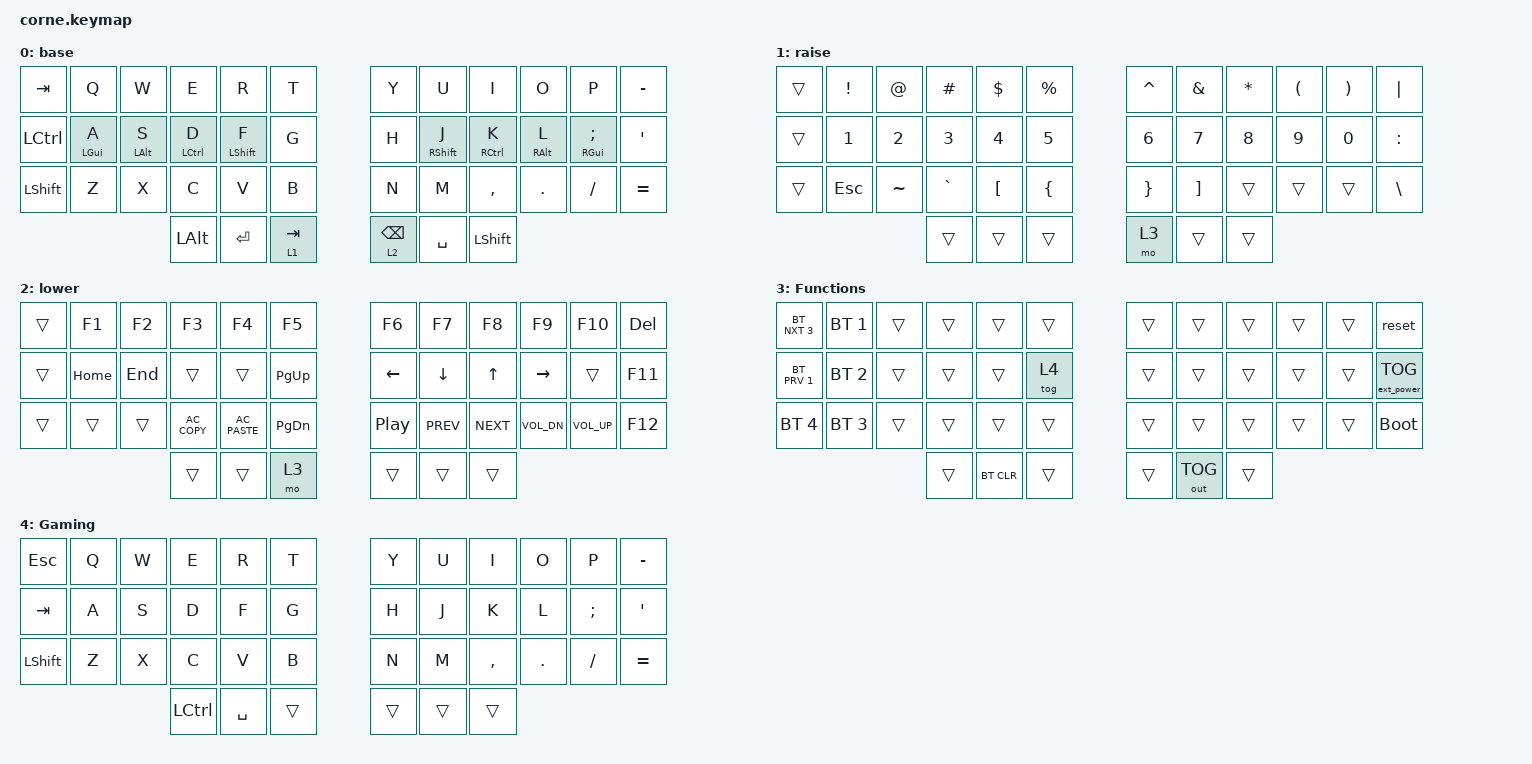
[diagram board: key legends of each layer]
/*
 * Copyright (c) 2020 The ZMK Contributors
 *
 * SPDX-License-Identifier: MIT
 */

#include <behaviors.dtsi>
#include <dt-bindings/zmk/keys.h>
#include <dt-bindings/zmk/bt.h>
#include <dt-bindings/zmk/ext_power.h>
#include <dt-bindings/zmk/outputs.h>

/ {
    behaviors {
        hm: homerow_mods {
            compatible = "zmk,behavior-hold-tap";
            label = "HOMEROW_MODS";
            #binding-cells = <2>;
            tapping-term-ms = <150>;
            quick-tap-ms = <0>;
            flavor = "tap-preferred";
            bindings =
                <&kp>,
                <&kp>;
        };
    };

    combos {
        compatible = "zmk,combos";

        ESCAPE_Combo {
            bindings = <&kp ESC>;
            key-positions = <19 20>;
        };

        Left_Bracket {
            bindings = <&kp LEFT_BRACKET>;
            key-positions = <4 5>;
        };

        Right_Bracket {
            bindings = <&kp RIGHT_BRACKET>;
            key-positions = <6 7>;
        };

        Left_Parethesis {
            bindings = <&kp LEFT_PARENTHESIS>;
            key-positions = <16 17>;
        };

        Right_Parenthesis {
            bindings = <&kp RIGHT_PARENTHESIS>;
            key-positions = <18 19>;
        };

        Left_Brace {
            bindings = <&kp LEFT_BRACE>;
            key-positions = <28 29>;
        };

        Right_Brace {
            bindings = <&kp RIGHT_BRACE>;
            key-positions = <30 31>;
        };

        Back_Slash {
            bindings = <&kp BACKSLASH>;
            key-positions = <4 31>;
        };

        Slash {
            bindings = <&kp SLASH>;
            key-positions = <28 7>;
        };

        Backspace {
            bindings = <&kp BACKSPACE>;
            key-positions = <3 4>;
        };

        Delete {
            bindings = <&kp DELETE>;
            key-positions = <7 8>;
        };

        Toggle_Gaming_Layer {
            bindings = <&to 4>;
            key-positions = <10 11>;
        };
    };

    macros {
    };

    keymap {
        compatible = "zmk,keymap";

        base {
            bindings = <
   &kp TAB       &kp Q       &kp W         &kp E         &kp R      &kp T                    &kp Y         &kp U           &kp I       &kp O          &kp P  &kp MINUS
 &kp LCTRL  &hm LGUI A  &hm LALT S   &hm LCTRL D  &hm LSHIFT F      &kp G                    &kp H  &hm RSHIFT J     &hm RCTRL K  &hm RALT L  &hm RGUI SEMI   &kp APOS
 &kp LSHFT       &kp Z       &kp X         &kp C         &kp V      &kp B                    &kp N         &kp M       &kp COMMA     &kp DOT       &kp FSLH  &kp EQUAL
                                    &kp LEFT_ALT     &kp ENTER  &lt 1 TAB          &lt 2 BACKSPACE     &kp SPACE  &kp LEFT_SHIFT
            >;
        };

        raise {
            bindings = <
 &trans  &kp EXCLAMATION        &kp AT      &kp HASH          &kp DLLR     &kp PERCENT                &kp CARET           &kp AMPS     &kp ASTRK  &kp LEFT_PARENTHESIS  &kp RIGHT_PARENTHESIS       &kp PIPE
 &trans     &kp NUMBER_1  &kp NUMBER_2  &kp NUMBER_3      &kp NUMBER_4    &kp NUMBER_5             &kp NUMBER_6       &kp NUMBER_7  &kp NUMBER_8          &kp NUMBER_9           &kp NUMBER_0      &kp COLON
 &trans          &kp ESC     &kp TILDE     &kp GRAVE  &kp LEFT_BRACKET  &kp LEFT_BRACE          &kp RIGHT_BRACE  &kp RIGHT_BRACKET        &trans                &trans                 &trans  &kp BACKSLASH
                                              &trans            &trans          &trans                    &mo 3             &trans        &trans
            >;
        };

        lower {
            bindings = <
 &trans    &kp F1   &kp F2         &kp F3          &kp F4         &kp F5                    &kp F6      &kp F7      &kp F8        &kp F9       &kp F10  &kp DELETE
 &trans  &kp HOME  &kp END         &trans          &trans    &kp PAGE_UP                  &kp LEFT    &kp DOWN      &kp UP     &kp RIGHT        &trans     &kp F11
 &trans    &trans   &trans  &kp C_AC_COPY  &kp C_AC_PASTE  &kp PAGE_DOWN          &kp C_PLAY_PAUSE  &kp C_PREV  &kp C_NEXT  &kp C_VOL_DN  &kp C_VOL_UP     &kp F12
                                   &trans          &trans          &mo 3                    &trans      &trans      &trans
            >;
        };

        Functions {
            bindings = <
 &bt BT_NXT 3  &bt BT_SEL 1  &trans  &trans      &trans  &trans          &trans        &trans  &trans  &trans  &trans             &reset
 &bt BT_PRV 1  &bt BT_SEL 2  &trans  &trans      &trans  &tog 4          &trans        &trans  &trans  &trans  &trans  &ext_power EP_TOG
 &bt BT_SEL 4  &bt BT_SEL 3  &trans  &trans      &trans  &trans          &trans        &trans  &trans  &trans  &trans        &bootloader
                                     &trans  &bt BT_CLR  &trans          &trans  &out OUT_TOG  &trans
            >;
        };

        Gaming {
            bindings = <
        &kp ESC   &kp Q   &kp W      &kp E      &kp R   &kp T           &kp Y   &kp U      &kp I    &kp O          &kp P  &kp MINUS
        &kp TAB   &kp A   &kp S      &kp D      &kp F   &kp G           &kp H   &kp J      &kp K    &kp L  &kp SEMICOLON   &kp APOS
 &kp LEFT_SHIFT   &kp Z   &kp X      &kp C      &kp V   &kp B           &kp N   &kp M  &kp COMMA  &kp DOT       &kp FSLH  &kp EQUAL
                                 &kp LCTRL  &kp SPACE  &trans          &trans  &trans     &trans
            >;
        };
    };
};
